AUTOSAR XML (schema 4-0-3)
package /ComponentTypes
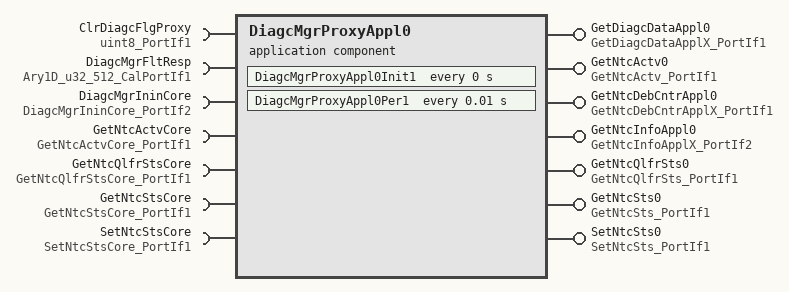
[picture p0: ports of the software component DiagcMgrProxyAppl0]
  application sw component type DiagcMgrProxyAppl0
    7 x provide port, all with server-com-spec{operation=Oper, queue-length=1}:
      GetDiagcDataAppl0: provided-interface=GetDiagcDataApplX_PortIf1
      GetNtcActv0: provided-interface=GetNtcActv_PortIf1
      GetNtcDebCntrAppl0: provided-interface=GetNtcDebCntrApplX_PortIf1
      GetNtcInfoAppl0: provided-interface=GetNtcInfoApplX_PortIf2
      GetNtcQlfrSts0: provided-interface=GetNtcQlfrSts_PortIf1
      GetNtcSts0: provided-interface=GetNtcSts_PortIf1
      SetNtcSts0: provided-interface=SetNtcSts_PortIf1
    7 x require port:
      ClrDiagcFlgProxy: nonqueued-receiver-com-spec{data-element=Val, filter=data-filter-type=ALWAYS, init-value=0}, required-interface=uint8_PortIf1
      DiagcMgrFltResp: parameter-require-com-spec{init-value=[0, 2147487488, 2147487488, 2147487488, 2147487488, 2147487488, 2147487488, 2147487488, 2147487488, 2147487488, 2147487488, 2147487488, 2147487488, 2147487488, 2147487488, 2147487488, 2147487488, 2147487488, 2147487488, 2147487488, 2147487488, 2147487488, 2147487488, 2147487488, 2147487488, 2147487488, 2147487488, 2147487488, 2147487488, 2147487488, 2147487488, 2147487488, 2147487488, 2147487488, 2147487488, 2147487488, 2147487488, 2147487488, 2147487488, 2147487488, 2147487488, 2147487488, 2147487488, 2147487488, 2147487488, 2147487488, 2147487488, 2147487488, 2147487488, 2147487488, 2147487488, 2147487488, 2147487488, 2147487488, 2147487488, 2147487488, 2147487488, 2147487488, 2147487488, 2147487488, 2147487488, 2147487488, 2147487488, 2147487488, 2147487488, 2147487488, 2147487488, 2147487488, 2147487488, 2147487488, 2147487488, 2147487488, 2147487488, 2147487488, 2147487488, 2147487488, 2147487488, 2147487488, 2147487488, 2147487488, 2147487488, 2147487488, 2147487488, 2147487488, 2147487488, 2147487488, 2147487488, 2147487488, 2147487488, 2147487488, 2147487488, 2147487488, 2147487488, 2147487488, 2147487488, 2147487488, 2147487488, 2147487488, 2147487488, 2147487488, 2147487488, 2147487488, 2147487488, 2147487488, 2147487488, 2147487488, 2147487488, 2147487488, 2147487488, 2147487488, 2147487488, 2147487488, 2147487488, 2147487488, 2147487488, 2147487488, 2147487488, 2147487488, 2147487488, 2147487488, 2147487488, 2147487488, 2147487488, 2147487488, 2147487488, 2147487488, 2147487488, 2147487488, 2147487488, 2147487488, 2147487488, 2147487488, 2147487488, 2147487488, 2147487488, 2147487488, 2147487488, 2147487488, 2147487488, 2147487488, 2147487488, 2147487488, 2147487488, 2147487488, 2147487488, 2147487488, 2147487488, 2147487488, 2147487488, 2147487488, 2147487488, 2147487488, 2147487488, 2147487488, 2147487488, 2147487488, 2147487488, 2147487488, 2147487488, 2147487488, 2147487488, 2147487488, 2147487488, 2147487488, 2147487488, 2147487488, 2147487488, 2147487488, 2147487488, 2147487488, 2147487488, 2147487488, 2147487488, 2147487488, 2147487488, 2147487488, 2147487488, 2147487488, 2147487488, 2147487488, 2147487488, 2147487488, 2147487488, 2147487488, 2147487488, 2147487488, 2147487488, 2147487488, 2147487488, 2147487488, 2147487488, 2147487488, 2147487488, 2147487488, 2147487488, 2147487488, 2147487488, 2147487488, 2147487488, 2147487488, 2147487488, 2147487488, 2147487488, 2147487488, 2147487488, 2147487488, 2147487488, 2147487488, 2147487488, 2147487488, 2147487488, 2147487488, 2147487488, 2147487488, 2147487488, 2147487488, 2147487488, 2147487488, 2147487488, 2147487488, 2147487488, 2147487488, 2147487488, 2147487488, 2147487488, 2147487488, 2147487488, 2147487488, 2147487488, 2147487488, 2147487488, 2147487488, 2147487488, 2147487488, 2147487488, 2147487488, 2147487488, 2147487488, 2147487488, 2147487488, 2147487488, 2147487488, 2147487488, 2147487488, 2147487488, 2147487488, 2147487488, 2147487488, 2147487488, 2147487488, 2147487488, 2147487488, 2147487488, 2147487488, 2147487488, 2147487488, 2147487488, 2147487488, 2147487488, 2147487488, 2147487488, 2147487488, 2147487488, 2147487488, 2147487488, 2147487488, 2147487488, 2147487488, 2147487488, 2147487488, 2147487488, 2147487488, 2147487488, 2147487488, 2147487488, 2147487488, 2147487488, 2147487488, 2147487488, 2147487488, 2147487488, 2147487488, 2147487488, 2147487488, 2147487488, 2147487488, 2147487488, 2147487488, 2147487488, 2147487488, 2147487488, 2147487488, 2147487488, 2147487488, 2147487488, 2147487488, 2147487488, 2147487488, 2147487488, 2147487488, 2147487488, 2147487488, 2147487488, 2147487488, 2147487488, 2147487488, 2147487488, 2147487488, 2147487488, 2147487488, 2147487488, 2147487488, 2147487488, 2147487488, 2147487488, 2147487488, 2147487488, 2147487488, 2147487488, 2147487488, 2147487488, 2147487488, 2147487488, 2147487488, 2147487488, 2147487488, 2147487488, 2147487488, 2147487488, 2147487488, 2147487488, 2147487488, 2147487488, 2147487488, 2147487488, 2147487488, 2147487488, 2147487488, 2147487488, 2147487488, 2147487488, 2147487488, 2147487488, 2147487488, 2147487488, 2147487488, 2147487488, 2147487488, 2147487488, 2147487488, 2147487488, 2147487488, 2147487488, 2147487488, 2147487488, 2147487488, 2147487488, 2147487488, 2147487488, 2147487488, 2147487488, 2147487488, 2147487488, 2147487488, 2147487488, 2147487488, 2147487488, 2147487488, 2147487488, 2147487488, 2147487488, 2147487488, 2147487488, 2147487488, 2147487488, 2147487488, 2147487488, 2147487488, 2147487488, 2147487488, 2147487488, 2147487488, 2147487488, 2147487488, 2147487488, 2147487488, 2147487488, 2147487488, 2147487488, 2147487488, 2147487488, 2147487488, 2147487488, 2147487488, 2147487488, 2147487488, 2147487488, 2147487488, 2147487488, 2147487488, 2147487488, 2147487488, 2147487488, 2147487488, 2147487488, 2147487488, 2147487488, 2147487488, 2147487488, 2147487488, 2147487488, 2147487488, 2147487488, 2147487488, 2147487488, 2147487488, 2147487488, 2147487488, 2147487488, 2147487488, 2147487488, 2147487488, 2147487488, 2147487488, 2147487488, 2147487488, 2147487488, 2147487488, 2147487488, 2147487488, 2147487488, 2147487488, 2147487488, 2147487488, 2147487488, 2147487488, 2147487488, 2147487488, 2147487488, 2147487488, 2147487488, 2147487488, 2147487488, 2147487488, 2147487488, 2147487488, 2147487488, 2147487488, 2147487488, 2147487488, 2147487488, 2147487488, 2147487488, 2147487488, 2147487488, 2147487488, 2147487488, 2147487488, 2147487488, 2147487488, 2147487488, 2147487488, 2147487488, 2147487488, 2147487488, 2147487488, 2147487488, 2147487488, 2147487488, 2147487488, 2147487488, 2147487488, 2147487488, 2147487488, 2147487488, 2147487488, 2147487488, 2147487488, 2147487488, 2147487488, 2147487488, 2147487488, 2147487488, 2147487488, 2147487488, 2147487488, 2147487488, 2147487488, 2147487488, 2147487488, 2147487488, 2147487488, 2147487488, 2147487488, 2147487488, 2147487488, 2147487488, 2147487488, 2147487488, 2147487488, 2147487488, 2147487488, 2147487488, 2147487488, 2147487488, 2147487488, 2147487488, 2147487488, 2147487488, 2147487488, 2147487488, 2147487488], parameter=Ary1D}, required-interface=Ary1D_u32_512_CalPortIf1
      DiagcMgrIninCore: required-interface=DiagcMgrIninCore_PortIf2
      GetNtcActvCore: required-interface=GetNtcActvCore_PortIf1
      GetNtcQlfrStsCore: required-interface=GetNtcQlfrStsCore_PortIf1
      GetNtcStsCore: required-interface=GetNtcStsCore_PortIf1
      SetNtcStsCore: required-interface=SetNtcStsCore_PortIf1
    behavior DiagcMgrProxyAppl0_InternalBehavior
      exclusive area DiagcMgrProxyAppl0
      ar-typed-per-instance-memorys:
        5 x data:
          DiagcData0: sw-calibration-access=READ-ONLY, type=DiagcDataRec1
          DiagcMgrNtcInfo0Ary: type=Ary1D_NtcInfoRec4_DiagcMgrProxyAppl0
          DiagcMgrNtcInfo0DebCntrAry: type=Ary1D_s16_DiagcMgrProxyAppl0
          PrevClrNtcFlg0: sw-calibration-access=READ-ONLY, type=uint8
          ProxySetNtcData0: sw-calibration-access=READ-ONLY, type=DiagcDataRec1
      timing event DiagcMgrProxyAppl0_InitEvent: start-on-event=DiagcMgrProxyAppl0Init1, period=0
      timing event TMT_DiagcMgrProxyAppl0Per1: start-on-event=DiagcMgrProxyAppl0Per1, period=0.01
      7 x operation invoked event:
        OIT_GetDiagcDataAppl0_Oper_GetDiagcDataAppl0_Oper: start-on-event=GetDiagcDataAppl0_Oper, operation=GetDiagcDataAppl0.Oper
        OIT_GetNtcActv0_Oper_GetNtcActv0_Oper: start-on-event=GetNtcActv0_Oper, operation=GetNtcActv0.Oper
        OIT_GetNtcDebCntrAppl0_Oper_GetNtcDebCntrAppl0_Oper: start-on-event=GetNtcDebCntrAppl0_Oper, operation=GetNtcDebCntrAppl0.Oper
        OIT_GetNtcInfoAppl0_Oper_GetNtcInfoAppl0_Oper: start-on-event=GetNtcInfoAppl0_Oper, operation=GetNtcInfoAppl0.Oper
        OIT_GetNtcQlfrSts0_Oper_GetNtcQlfrSts0_Oper: start-on-event=GetNtcQlfrSts0_Oper, operation=GetNtcQlfrSts0.Oper
        OIT_GetNtcSts0_Oper_GetNtcSts0_Oper: start-on-event=GetNtcSts0_Oper, operation=GetNtcSts0.Oper
        OIT_SetNtcSts0_Oper_SetNtcSts0_Oper: start-on-event=SetNtcSts0_Oper, operation=SetNtcSts0.Oper
      9 x runnable:
        DiagcMgrProxyAppl0Init1
          sync call SC_DiagcMgrIninCore_Oper: operation=DiagcMgrIninCore.Oper, timeout=0
        DiagcMgrProxyAppl0Per1: can-enter-exclusive-area=DiagcMgrProxyAppl0
          data-receive-point-by-arguments:
            access REC_ClrNtcFlg_Val: accessed-variable=ClrDiagcFlgProxy.Val
        GetDiagcDataAppl0_Oper
        GetNtcActv0_Oper: can-be-invoked-concurrently=true
          sync call SC_GetNtcActvCore_Oper: operation=GetNtcActvCore.Oper, timeout=0
        GetNtcDebCntrAppl0_Oper
        GetNtcInfoAppl0_Oper
        GetNtcQlfrSts0_Oper: can-be-invoked-concurrently=true
          sync call SC_GetNtcQlfrStsCore_Oper: operation=GetNtcQlfrStsCore.Oper, timeout=0
        GetNtcSts0_Oper: can-be-invoked-concurrently=true
          sync call SC_GetNtcStsCore_Oper: operation=GetNtcStsCore.Oper, timeout=0
        SetNtcSts0_Oper: can-be-invoked-concurrently=true
          sync call SC_SetNtcStsCore_Oper: operation=SetNtcStsCore.Oper, timeout=0
  swc implementation DiagcMgrProxyAppl0_Implementation: behavior=DiagcMgrProxyAppl0_InternalBehavior
    code-descriptors:
      code Default: artifact-descriptors=autosar-engineering-object={short-label=Default, category=SWSRC}
